# MCXN947_cm33_core0 register map
Vendor: nxp.com; File version: 1.0
CPU: CM33 r2p0, little endian, MPU, FPU, VTOR, 3 interrupt priority bits
Registers are 32-bit, read-write, reset 0x0 unless marked. A register's access mark holds for its fields unless they carry their own. Offsets are from the block's base; [hi:lo] are bit positions; lines under a group give offsets from that group; {n}, {i} and the like mark numbered series; 'fields as' and 'values as' point back to an identical list.

## AHBSC
Base 0x40120000
Same registers: AHBSC_ALIAS1 0x40121000, AHBSC_ALIAS2 0x40122000, AHBSC_ALIAS3 0x40123000
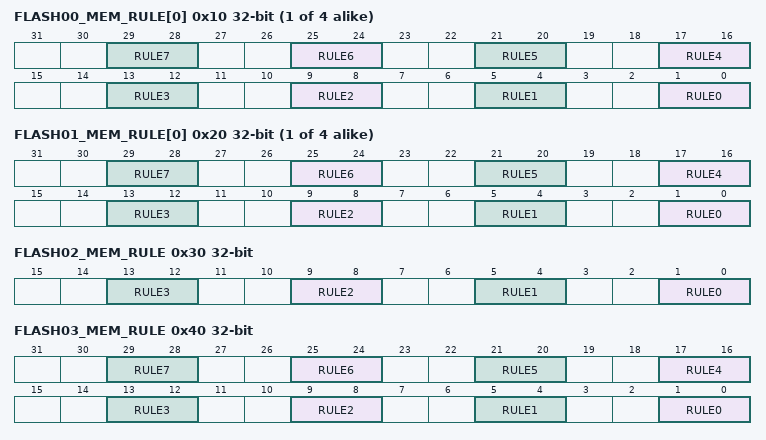
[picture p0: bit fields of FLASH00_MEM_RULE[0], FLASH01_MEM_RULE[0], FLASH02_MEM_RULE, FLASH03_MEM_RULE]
{0x10+4i} FLASH00_MEM_RULE[{i}] (i=0..3) — Flash Memory Rule
  [all] fields
    0=NONSECURE_NONPRIV_USER_ALLOWED (Non-secure and non-privilege user access allowed); 1=NONSECURE_PRIV_USER_ALLOWED (Non-secure and privilege access allowed); 2=SECURE_NONPRIV_USER_ALLOWED (Secure and non-privilege user access allowed); 3=SECURE_PRIV_USER_ALLOWED (Secure and privilege user access allowed)
  [4n+1:4n] RULE{n} (n=0..7)
{0x20+4i} FLASH01_MEM_RULE[{i}] (i=0..3) — Flash Memory Rule
  fields as FLASH00_MEM_RULE[0]
0x30 FLASH02_MEM_RULE — Flash Memory Rule
  [all] fields
    values as the fields of FLASH00_MEM_RULE[0]
  [4n+1:4n] RULE{n} (n=0..3)
0x40 FLASH03_MEM_RULE — Flash Memory Rule
  fields as FLASH00_MEM_RULE[0]
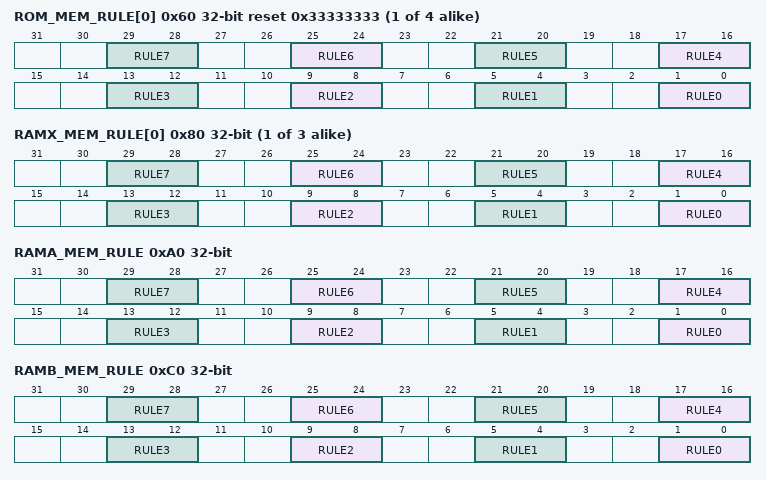
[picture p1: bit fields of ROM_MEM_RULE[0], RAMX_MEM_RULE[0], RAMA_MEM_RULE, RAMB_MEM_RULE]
{0x60+4i} ROM_MEM_RULE[{i}] (i=0..3) reset 0x33333333 — ROM Memory Rule
  fields as FLASH00_MEM_RULE[0]
{0x80+4i} RAMX_MEM_RULE[{i}] (i=0..2) — RAMX Memory Rule
  fields as FLASH00_MEM_RULE[0]
0xA0 RAMA_MEM_RULE — RAMA Memory Rule 0
  fields as FLASH00_MEM_RULE[0]
0xC0 RAMB_MEM_RULE — RAMB Memory Rule
  fields as FLASH00_MEM_RULE[0]
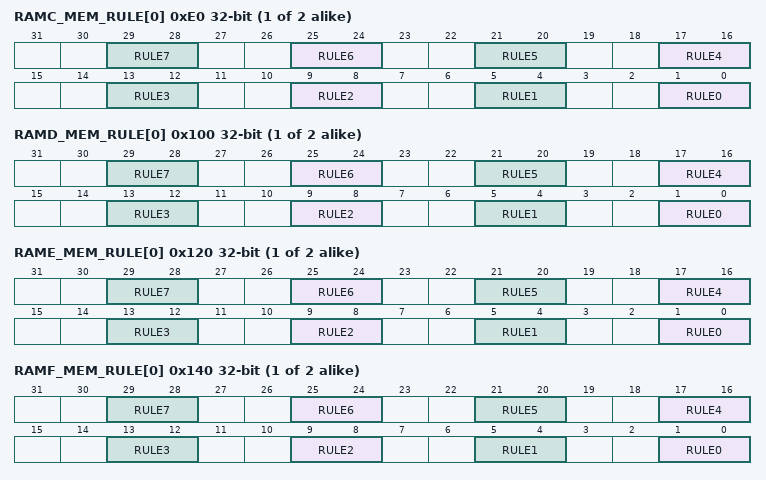
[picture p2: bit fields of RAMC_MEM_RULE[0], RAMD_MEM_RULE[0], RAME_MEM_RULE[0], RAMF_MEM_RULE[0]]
{0xE0+4i} RAMC_MEM_RULE[{i}] (i=0..1) — RAMC Memory Rule
  fields as FLASH00_MEM_RULE[0]
{0x100+4i} RAMD_MEM_RULE[{i}] (i=0..1) — RAMD Memory Rule
  fields as FLASH00_MEM_RULE[0]
{0x120+4i} RAME_MEM_RULE[{i}] (i=0..1) — RAME Memory Rule
  fields as FLASH00_MEM_RULE[0]
{0x140+4i} RAMF_MEM_RULE[{i}] (i=0..1) — RAMF Memory Rule
  fields as FLASH00_MEM_RULE[0]
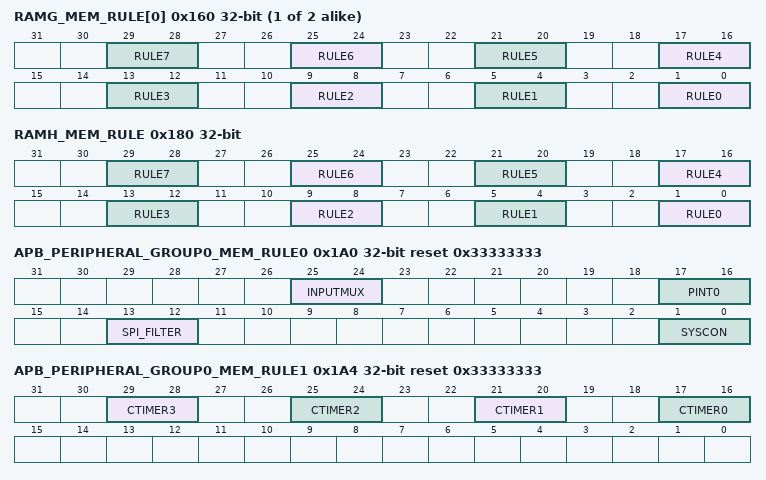
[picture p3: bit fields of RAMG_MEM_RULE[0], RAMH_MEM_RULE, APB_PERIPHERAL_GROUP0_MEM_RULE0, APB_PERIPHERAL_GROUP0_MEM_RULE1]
{0x160+4i} RAMG_MEM_RULE[{i}] (i=0..1) — RAMG Memory Rule
  fields as FLASH00_MEM_RULE[0]
0x180 RAMH_MEM_RULE — RAMH Memory Rule
  fields as FLASH00_MEM_RULE[0]
0x1A0 APB_PERIPHERAL_GROUP0_MEM_RULE0 reset 0x33333333 — APB Bridge Group 0 Memory Rule 0
  [all] fields
    values as the fields of FLASH00_MEM_RULE[0]
  [25:24] INPUTMUX
  [17:16] PINT0
  [13:12] SPI_FILTER — GPIO0
  [1:0] SYSCON
0x1A4 APB_PERIPHERAL_GROUP0_MEM_RULE1 reset 0x33333333 — APB Bridge Group 0 Memory Rule 1
  [all] fields
    values as the fields of FLASH00_MEM_RULE[0]
  [29:28] CTIMER3
  [25:24] CTIMER2
  [21:20] CTIMER1 write-1-clears
  [17:16] CTIMER0 write-1-clears
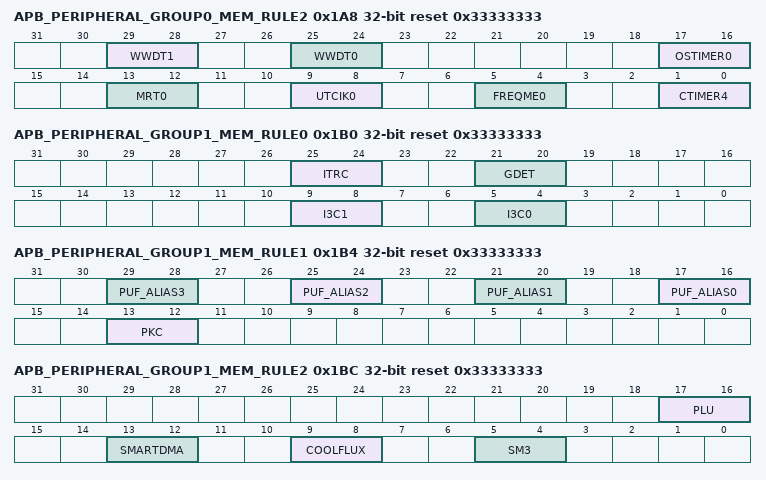
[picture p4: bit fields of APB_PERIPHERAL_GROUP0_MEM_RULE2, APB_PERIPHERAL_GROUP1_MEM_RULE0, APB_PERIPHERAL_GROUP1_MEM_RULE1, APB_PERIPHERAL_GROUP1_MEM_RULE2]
0x1A8 APB_PERIPHERAL_GROUP0_MEM_RULE2 reset 0x33333333 — APB Bridge Group 0 Rule 2
  [all] fields
    values as the fields of FLASH00_MEM_RULE[0]
  [29:28] WWDT1
  [25:24] WWDT0
  [17:16] OSTIMER0
  [13:12] MRT0
  [9:8] UTCIK0
  [5:4] FREQME0
  [1:0] CTIMER4
0x1AC APB_PERIPHERAL_GROUP0_MEM_RULE3 reset 0x33333333 — APB Bridge Group 0 Memory Rule 3
  [13:12] CACHE64_POLSEL0
    values as the fields of FLASH00_MEM_RULE[0]
0x1B0 APB_PERIPHERAL_GROUP1_MEM_RULE0 reset 0x33333333 — APB Bridge Group 1 Memory Rule 0
  [all] fields
    values as the fields of FLASH00_MEM_RULE[0]
  [25:24] ITRC
  [21:20] GDET
  [9:8] I3C1
  [5:4] I3C0
0x1B4 APB_PERIPHERAL_GROUP1_MEM_RULE1 reset 0x33333333 — APB Bridge Group 1 Memory Rule 1
  [all] fields
    values as the fields of FLASH00_MEM_RULE[0]
  [4n+17:4n+16] PUF_ALIAS{n} (n=0..3)
  [13:12] PKC
0x1BC APB_PERIPHERAL_GROUP1_MEM_RULE2 reset 0x33333333 — APB Bridge Group 1 Memory Rule 2
  [all] fields
    values as the fields of FLASH00_MEM_RULE[0]
  [17:16] PLU
  [13:12] SMARTDMA
  [9:8] COOLFLUX
  [5:4] SM3
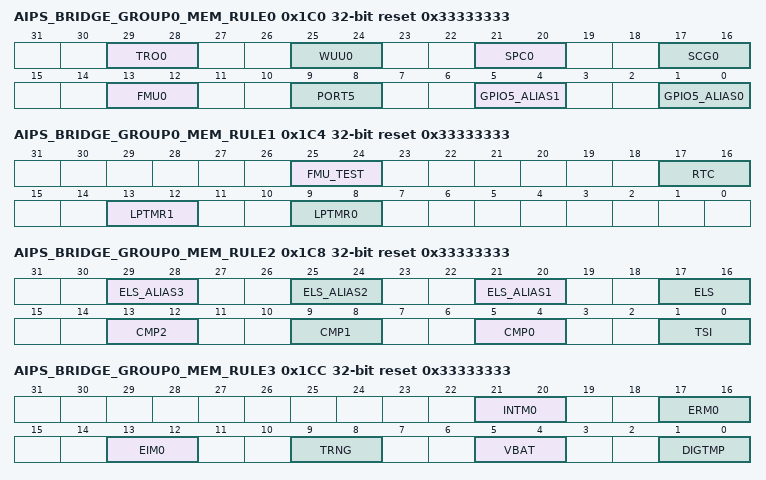
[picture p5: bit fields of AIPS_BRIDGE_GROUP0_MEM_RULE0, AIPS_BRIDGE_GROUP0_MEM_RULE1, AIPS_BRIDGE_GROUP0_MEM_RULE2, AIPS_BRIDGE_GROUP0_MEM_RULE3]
0x1C0 AIPS_BRIDGE_GROUP0_MEM_RULE0 reset 0x33333333 — AIPS Bridge Group 0 Memory Rule 0
  [all] fields
    values as the fields of FLASH00_MEM_RULE[0]
  [29:28] TRO0
  [25:24] WUU0
  [21:20] SPC0
  [17:16] SCG0
  [13:12] FMU0
  [9:8] PORT5
  [5:4] GPIO5_ALIAS1 — GPIO5_ALIAS2
  [1:0] GPIO5_ALIAS0
0x1C4 AIPS_BRIDGE_GROUP0_MEM_RULE1 reset 0x33333333 — AIPS Bridge Group 0 Memory Rule 1
  [all] fields
    values as the fields of FLASH00_MEM_RULE[0]
  [25:24] FMU_TEST
  [17:16] RTC
  [13:12] LPTMR1
  [9:8] LPTMR0
0x1C8 AIPS_BRIDGE_GROUP0_MEM_RULE2 reset 0x33333333 — AIPS Bridge Group 0 Memory Rule 2
  [all] fields
    values as the fields of FLASH00_MEM_RULE[0]
  [29:28] ELS_ALIAS3
  [25:24] ELS_ALIAS2
  [21:20] ELS_ALIAS1
  [17:16] ELS
  [13:12] CMP2
  [9:8] CMP1
  [5:4] CMP0
  [1:0] TSI
0x1CC AIPS_BRIDGE_GROUP0_MEM_RULE3 reset 0x33333333 — AIPS Bridge Group 0 Memory Rule 3
  [all] fields
    values as the fields of FLASH00_MEM_RULE[0]
  [21:20] INTM0
  [17:16] ERM0
  [13:12] EIM0
  [9:8] TRNG
  [5:4] VBAT
  [1:0] DIGTMP
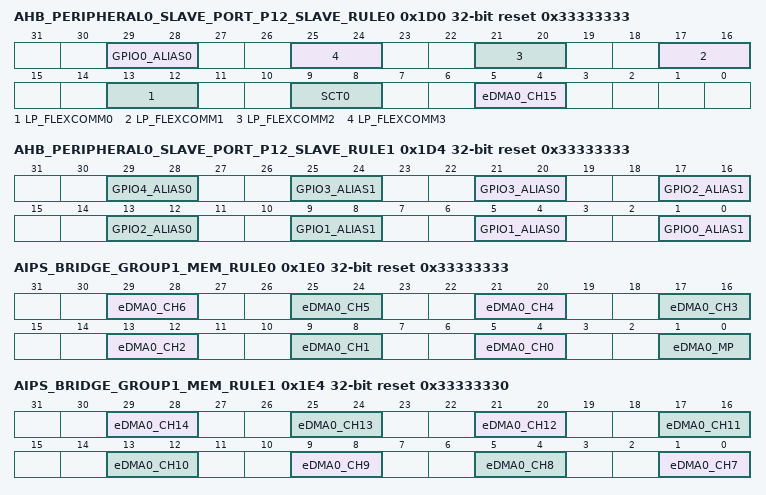
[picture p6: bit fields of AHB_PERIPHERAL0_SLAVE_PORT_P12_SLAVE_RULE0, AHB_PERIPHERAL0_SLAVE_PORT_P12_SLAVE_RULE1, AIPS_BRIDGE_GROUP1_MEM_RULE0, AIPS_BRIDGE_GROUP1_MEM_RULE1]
0x1D0 AHB_PERIPHERAL0_SLAVE_PORT_P12_SLAVE_RULE0 reset 0x33333333 — AHB Peripheral 0 Slave Port 12 Slave Rule 0
  [all] fields
    values as the fields of FLASH00_MEM_RULE[0]
  [29:28] GPIO0_ALIAS0
  [4n+13:4n+12] LP_FLEXCOMM{n} (n=0..3)
  [9:8] SCT0
  [5:4] eDMA0_CH15
0x1D4 AHB_PERIPHERAL0_SLAVE_PORT_P12_SLAVE_RULE1 reset 0x33333333 — AHB Peripheral 0 Slave Port 12 Slave Rule 1
  [all] fields
    values as the fields of FLASH00_MEM_RULE[0]
  [8n-3:8n-4] GPIO{n}_ALIAS0 (n=1..4)
  [8n+1:8n] GPIO{n}_ALIAS1 (n=0..3)
0x1D8 AHB_PERIPHERAL0_SLAVE_PORT_P12_SLAVE_RULE2 reset 0x33333333 — AHB Peripheral 0 Slave Port 12 Slave Rule 2
  [1:0] GPIO4_ALIAS1
    values as the fields of FLASH00_MEM_RULE[0]
0x1E0 AIPS_BRIDGE_GROUP1_MEM_RULE0 reset 0x33333333 — AIPS Bridge Group 1 Rule 0
  [all] fields
    values as the fields of FLASH00_MEM_RULE[0]
  [29:28] eDMA0_CH6
  [25:24] eDMA0_CH5
  [21:20] eDMA0_CH4
  [17:16] eDMA0_CH3 — FLEXSPI0 Registers
  [13:12] eDMA0_CH2
  [9:8] eDMA0_CH1
  [5:4] eDMA0_CH0
  [1:0] eDMA0_MP
0x1E4 AIPS_BRIDGE_GROUP1_MEM_RULE1 reset 0x33333330 — AIPS Bridge Group 1 Rule 1
  [all] fields
    values as the fields of FLASH00_MEM_RULE[0]
  [29:28] eDMA0_CH14
  [25:24] eDMA0_CH13
  [21:20] eDMA0_CH12
  [17:16] eDMA0_CH11 — FLEXSPI0
  [4n-27:4n-28] eDMA0_CH{n} (n=7..10)
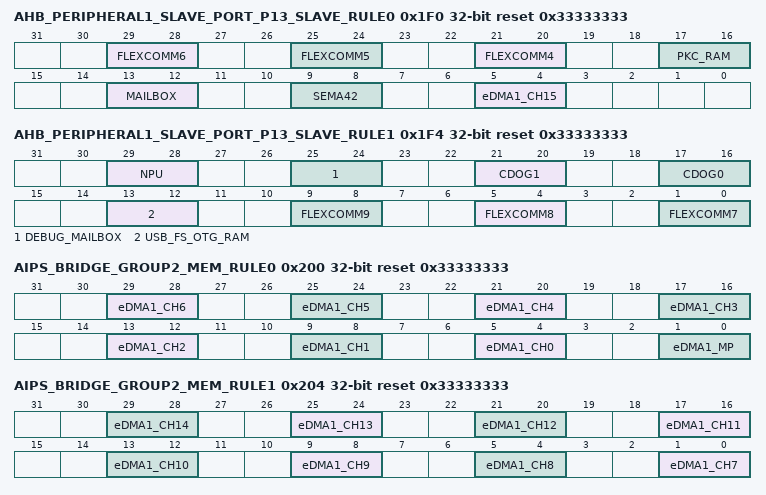
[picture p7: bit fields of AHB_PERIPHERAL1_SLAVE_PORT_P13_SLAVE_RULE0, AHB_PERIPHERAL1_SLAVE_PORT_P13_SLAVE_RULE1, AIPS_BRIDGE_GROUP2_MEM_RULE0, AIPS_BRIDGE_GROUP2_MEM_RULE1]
0x1F0 AHB_PERIPHERAL1_SLAVE_PORT_P13_SLAVE_RULE0 reset 0x33333333 — AHB Peripheral 1 Slave Port 13 Slave Rule 0
  [all] fields
    values as the fields of FLASH00_MEM_RULE[0]
  [29:28] FLEXCOMM6
  [25:24] FLEXCOMM5
  [21:20] FLEXCOMM4
  [17:16] PKC_RAM
  [13:12] MAILBOX
  [9:8] SEMA42
  [5:4] eDMA1_CH15
0x1F4 AHB_PERIPHERAL1_SLAVE_PORT_P13_SLAVE_RULE1 reset 0x33333333 — AHB Peripheral 1 Slave Port 13 Slave Rule 1
  [all] fields
    values as the fields of FLASH00_MEM_RULE[0]
  [29:28] NPU
  [25:24] DEBUG_MAILBOX
  [21:20] CDOG1
  [17:16] CDOG0
  [13:12] USB_FS_OTG_RAM
  [9:8] FLEXCOMM9
  [5:4] FLEXCOMM8
  [1:0] FLEXCOMM7
0x1F8 AHB_PERIPHERAL1_SLAVE_PORT_P13_SLAVE_RULE2 reset 0x33333333 — AHB Peripheral 1 Slave Port 13 Slave Rule 2
  [1:0] POWERQUAD
    values as the fields of FLASH00_MEM_RULE[0]
0x200 AIPS_BRIDGE_GROUP2_MEM_RULE0 reset 0x33333333 — AIPS Bridge Group 2 Rule 0
  [all] fields
    values as the fields of FLASH00_MEM_RULE[0]
  [4n+5:4n+4] eDMA1_CH{n} (n=0..6)
  [1:0] eDMA1_MP
0x204 AIPS_BRIDGE_GROUP2_MEM_RULE1 reset 0x33333333 — AIPS Bridge Group 2 Memory Rule 1
  [all] fields
    values as the fields of FLASH00_MEM_RULE[0]
  [4n-27:4n-28] eDMA1_CH{n} (n=7..14)
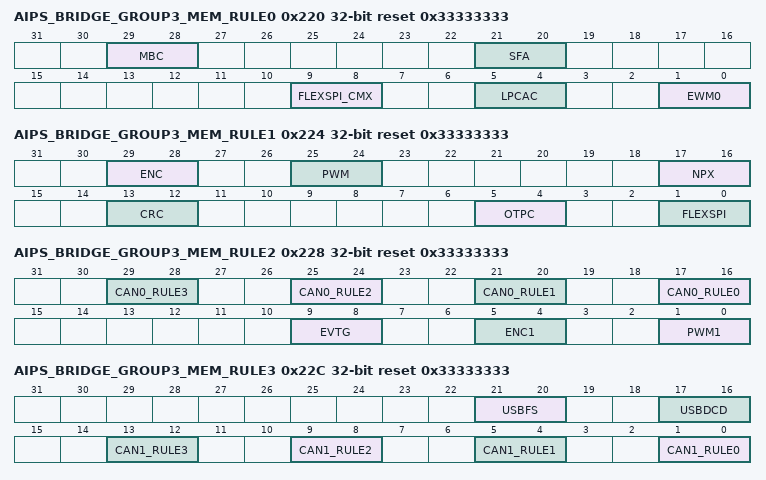
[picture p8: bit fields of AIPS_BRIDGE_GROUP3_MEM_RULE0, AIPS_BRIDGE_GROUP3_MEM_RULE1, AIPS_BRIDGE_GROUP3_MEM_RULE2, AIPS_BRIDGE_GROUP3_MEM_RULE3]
0x220 AIPS_BRIDGE_GROUP3_MEM_RULE0 reset 0x33333333 — AIPS Bridge Group 3 Rule 0
  [all] fields
    values as the fields of FLASH00_MEM_RULE[0]
  [29:28] MBC
  [21:20] SFA
  [9:8] FLEXSPI_CMX
  [5:4] LPCAC
  [1:0] EWM0
0x224 AIPS_BRIDGE_GROUP3_MEM_RULE1 reset 0x33333333 — AIPS Bridge Group 3 Memory Rule 1
  [all] fields
    values as the fields of FLASH00_MEM_RULE[0]
  [29:28] ENC
  [25:24] PWM
  [17:16] NPX
  [13:12] CRC
  [5:4] OTPC
  [1:0] FLEXSPI
0x228 AIPS_BRIDGE_GROUP3_MEM_RULE2 reset 0x33333333 — AIPS Bridge Group 3 Rule 2
  [all] fields
    values as the fields of FLASH00_MEM_RULE[0]
  [4n+17:4n+16] CAN0_RULE{n} (n=0..3)
  [9:8] EVTG
  [5:4] ENC1
  [1:0] PWM1
0x22C AIPS_BRIDGE_GROUP3_MEM_RULE3 reset 0x33333333 — AIPS Bridge Group 3 Rule 3
  [all] fields
    values as the fields of FLASH00_MEM_RULE[0]
  [21:20] USBFS
  [17:16] USBDCD
  [4n+1:4n] CAN1_RULE{n} (n=0..3)
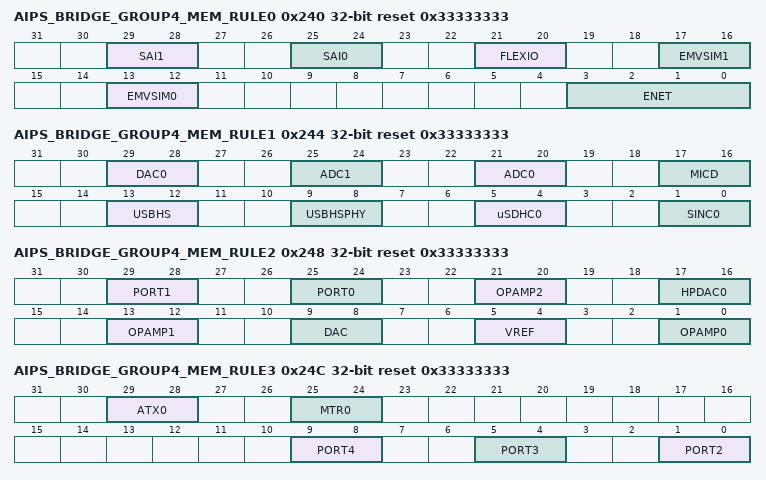
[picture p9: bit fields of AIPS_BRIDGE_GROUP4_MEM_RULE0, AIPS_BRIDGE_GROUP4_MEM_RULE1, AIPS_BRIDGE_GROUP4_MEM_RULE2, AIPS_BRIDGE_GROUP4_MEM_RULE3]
0x240 AIPS_BRIDGE_GROUP4_MEM_RULE0 reset 0x33333333 — AIPS Bridge Group 4 Rule 0
  [all] fields
    values as the fields of FLASH00_MEM_RULE[0]
  [29:28] SAI1
  [25:24] SAI0
  [21:20] FLEXIO
  [17:16] EMVSIM1
  [13:12] EMVSIM0
  [3:0] ENET
0x244 AIPS_BRIDGE_GROUP4_MEM_RULE1 reset 0x33333333 — AIPS Bridge Group 4 Rule 1
  [all] fields
    values as the fields of FLASH00_MEM_RULE[0]
  [29:28] DAC0
  [25:24] ADC1
  [21:20] ADC0
  [17:16] MICD
  [13:12] USBHS
  [9:8] USBHSPHY
  [5:4] uSDHC0
  [1:0] SINC0
0x248 AIPS_BRIDGE_GROUP4_MEM_RULE2 reset 0x33333333 — AIPS Bridge Group 4 Rule 2
  [all] fields
    values as the fields of FLASH00_MEM_RULE[0]
  [29:28] PORT1
  [25:24] PORT0
  [21:20] OPAMP2
  [17:16] HPDAC0
  [13:12] OPAMP1
  [9:8] DAC
  [5:4] VREF
  [1:0] OPAMP0
0x24C AIPS_BRIDGE_GROUP4_MEM_RULE3 reset 0x33333333 — AIPS Bridge Group 4 Rule 3
  [all] fields
    values as the fields of FLASH00_MEM_RULE[0]
  [29:28] ATX0
  [25:24] MTR0
  [9:8] PORT4
  [5:4] PORT3
  [1:0] PORT2
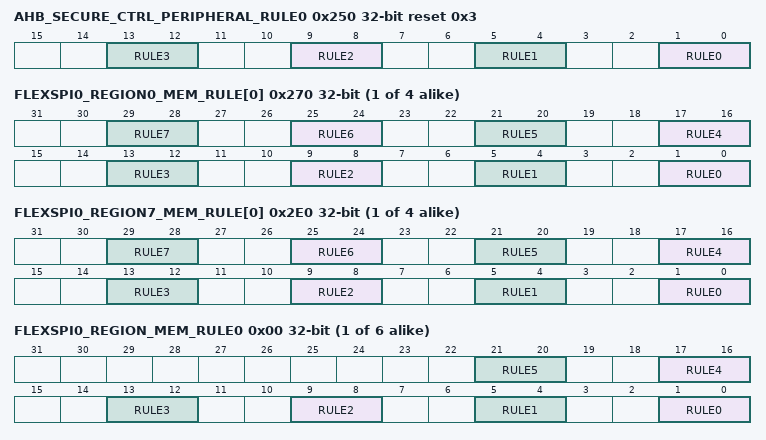
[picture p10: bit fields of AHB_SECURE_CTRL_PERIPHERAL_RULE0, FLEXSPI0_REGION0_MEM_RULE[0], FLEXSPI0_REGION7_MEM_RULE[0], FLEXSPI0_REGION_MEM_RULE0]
0x250 AHB_SECURE_CTRL_PERIPHERAL_RULE0 reset 0x3 — AHB Secure Control Peripheral Rule 0
  fields as FLASH02_MEM_RULE
{0x270+4i} FLEXSPI0_REGION0_MEM_RULE[{i}] (i=0..3) — FLEXSPI0 Region 0 Memory Rule
  fields as FLASH00_MEM_RULE[0]
{0x280+0x10*i} FLEXSPI0_REGION1_6_MEM_RULE[{i}] (i=0..5) group
  0x00 FLEXSPI0_REGION_MEM_RULE0 — FLEXSPI0 Region index Memory Rule 0
    [all] fields
      values as the fields of FLASH00_MEM_RULE[0]
    [4n+1:4n] RULE{n} (n=0..5)
{0x2E0+4i} FLEXSPI0_REGION7_MEM_RULE[{i}] (i=0..3) — FLEXSPI0 Region 7 Memory Rule
  fields as FLASH00_MEM_RULE[0]
{0x2F0+0x10*i} FLEXSPI0_REGION8_13_MEM_RULE[{i}] (i=0..5) group
  0x00 FLEXSPI0_REGION_MEM_RULE0 — FLEXSPI0 Region index Memory Rule 0
    fields as FLEXSPI0_REGION1_6_MEM_RULE[0].FLEXSPI0_REGION_MEM_RULE0
{0xE00+4i} SEC_VIO_ADDR[{i}] (i=0..31) ro — Security Violation Address
  [31:0] SEC_VIO_ADDR — Security violation address for AHB layer a reset value 0
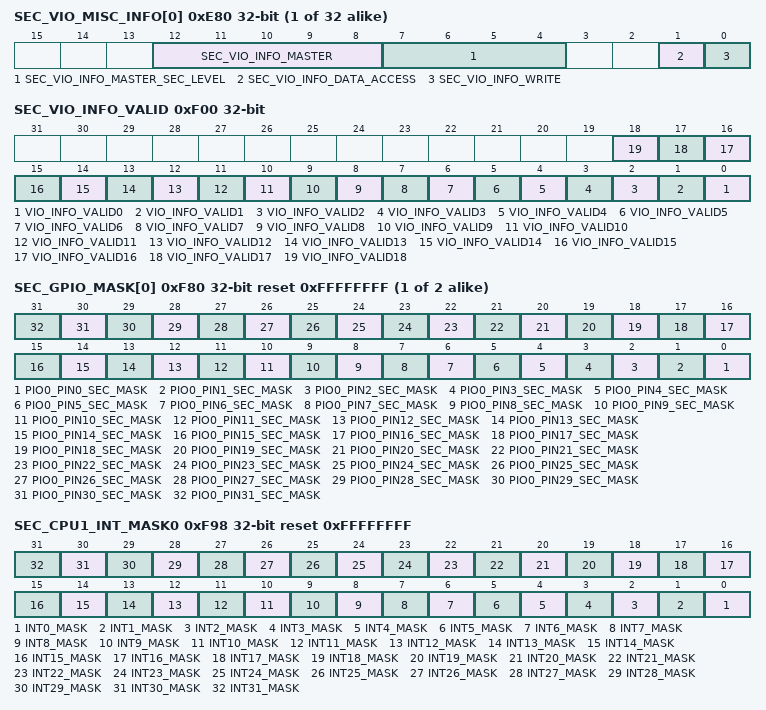
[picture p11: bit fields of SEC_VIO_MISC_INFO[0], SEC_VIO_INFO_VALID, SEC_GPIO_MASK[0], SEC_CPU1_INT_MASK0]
{0xE80+4i} SEC_VIO_MISC_INFO[{i}] (i=0..31) ro — Security Violation Miscellaneous Information at Address
  [12:8] SEC_VIO_INFO_MASTER — Security violation master number
    0=CPU0_CODE (M33 Code); 1=CPU0_SYS (M33 System); 2=CPU1_CODE (CPU1 (Mirco-CM33) Code); 3=SDMA_INSTR (SMARTDMA Instruction); 4=CPU1_SYS (CPU1 (Mirco-CM33) system); 5=SDMA_DATA (SMARTDMA Data); 6=eDMA0; 7=eDMA1; 8=PKC; 9=CSSV2 (ELS S50); 10=PQ (PKC M0); 11=NPUO (NPU Operands); 12=DSPI (DSP Instruction); 13=DSPX; 14=DSPY; 16=NPUD (NPU Data); 17=USB_FS; 18=ETHERNET; 19=USB_HS; 20=USDHC
  [7:4] SEC_VIO_INFO_MASTER_SEC_LEVEL — Security Violation Info Master Security Level
  [1] SEC_VIO_INFO_DATA_ACCESS — Security Violation Info Data Access
    0=CODE; 1=DATA
  [0] SEC_VIO_INFO_WRITE — Security violation access read/write indicator
    0=READ (Read access); 1=WRITE (Write access)
0xF00 SEC_VIO_INFO_VALID write-1-clears — Security Violation Info Validity for Address
  [all] fields
    0=NOT_VALID; 1=VALID
  [n] VIO_INFO_VALID{n} write-1-clears (n=0..18) — Violation information valid flag for AHB port {n}
{0xF80+4i} SEC_GPIO_MASK[{i}] (i=0..1) reset 0xFFFFFFFF — GPIO Mask for Port index
  [all] fields
    0=MASKED; 1=NOT_MASKED
  [n] PIO0_PIN{n}_SEC_MASK (n=0..31) — Mask bit
0xF98 SEC_CPU1_INT_MASK0 reset 0xFFFFFFFF — Secure Interrupt Mask 0 for CPU1
  [all] fields
    0=MASKED; 1=NOT_MASKED
  [n] INT{n}_MASK (n=0..31) — Mask bit
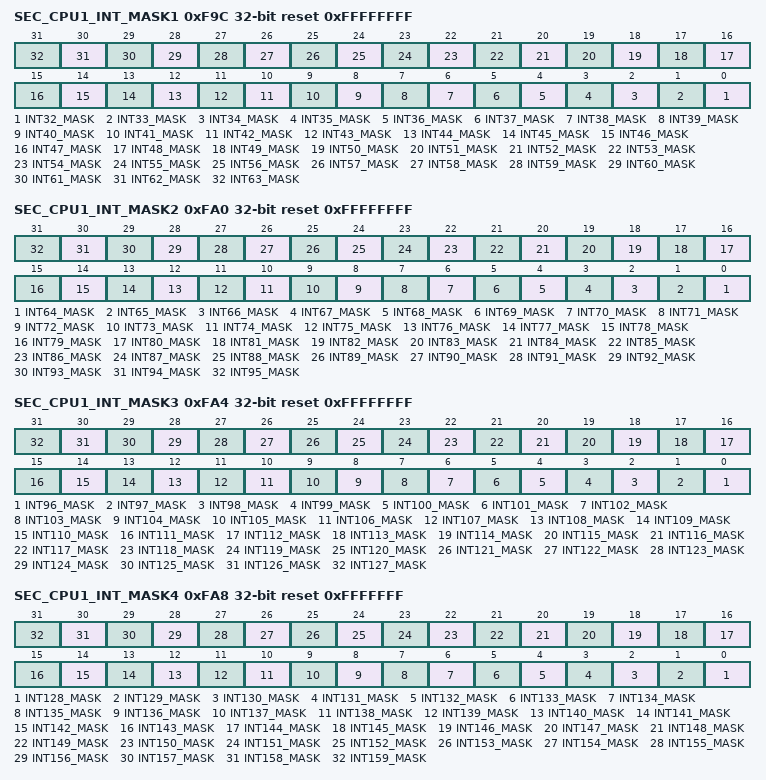
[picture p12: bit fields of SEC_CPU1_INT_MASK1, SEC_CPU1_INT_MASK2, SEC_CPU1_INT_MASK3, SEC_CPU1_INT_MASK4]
0xF9C SEC_CPU1_INT_MASK1 reset 0xFFFFFFFF — Secure Interrupt Mask 1 for CPU1
  [all] fields
    0=MASKED; 1=NOT_MASKED
  [n-32] INT{n}_MASK (n=32..63) — Mask bit
0xFA0 SEC_CPU1_INT_MASK2 reset 0xFFFFFFFF — Secure Interrupt Mask 2 for CPU1
  [all] fields
    0=MASKED; 1=NOT_MASKED
  [n-64] INT{n}_MASK (n=64..95) — Mask bit
0xFA4 SEC_CPU1_INT_MASK3 reset 0xFFFFFFFF — Secure Interrupt Mask 3 for CPU1
  [all] fields
    0=MASKED; 1=NOT_MASKED
  [n-96] INT{n}_MASK (n=96..127) — Mask bit
0xFA8 SEC_CPU1_INT_MASK4 reset 0xFFFFFFF — Secure Interrupt Mask 4 for CPU1
  [all] fields
    0=MASKED; 1=NOT_MASKED
  [n-128] INT{n}_MASK (n=128..159) — Mask bit
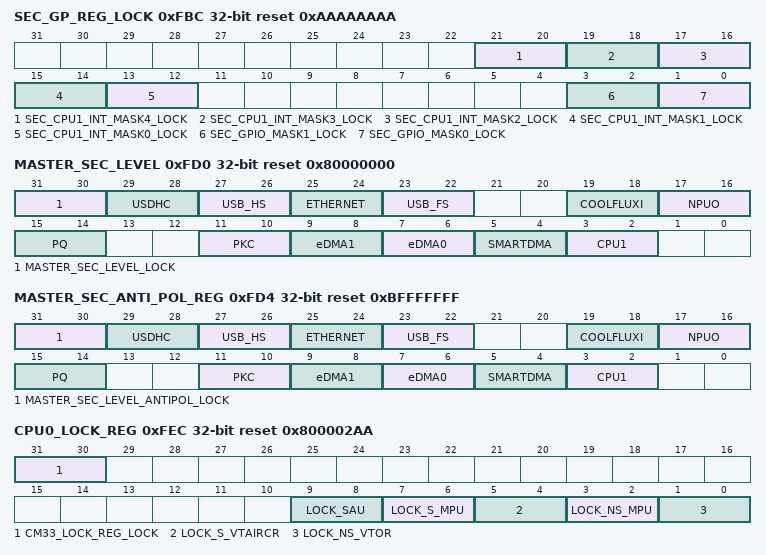
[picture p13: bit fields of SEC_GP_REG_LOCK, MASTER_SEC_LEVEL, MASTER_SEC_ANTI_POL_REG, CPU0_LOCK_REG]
0xFBC SEC_GP_REG_LOCK rw-once reset 0xAAAAAAAA — Secure Mask Lock
  [21:20] SEC_CPU1_INT_MASK4_LOCK
    1=CANNOT_BE_WRITTEN (SEC_CPU1_INT_MASK4 cannot be written); 2=CAN_BE_WRITTEN (SEC_CPU1_INT_MASK4 can be written)
  [19:18] SEC_CPU1_INT_MASK3_LOCK
    1=CANNOT_BE_WRITTEN (SEC_CPU1_INT_MASK3 cannot be written); 2=CAN_BE_WRITTEN (SEC_CPU1_INT_MASK3 can be written)
  [17:16] SEC_CPU1_INT_MASK2_LOCK
    1=CANNOT_BE_WRITTEN (SEC_CPU1_INT_MASK2 cannot be written); 2=CAN_BE_WRITTEN (SEC_CPU1_INT_MASK2 can be written)
  [15:14] SEC_CPU1_INT_MASK1_LOCK — SEC_GPIO_MASK1 Lock
    1=CANNOT_BE_WRITTEN (SEC_GPIO_MASK1 cannot be written); 2=CAN_BE_WRITTEN (SEC_GPIO_MASK1 can be written)
  [13:12] SEC_CPU1_INT_MASK0_LOCK — SSEC_CPU1_INT_MASK0 Lock
    1=CANNOT_BE_WRITTEN (SEC_GPIO_MASK0 cannot be written); 2=CAN_BE_WRITTEN (SEC_GPIO_MASK0 can be written)
  [3:2] SEC_GPIO_MASK1_LOCK — Secure GPIO _MASK1 Lock
    values as SEC_CPU1_INT_MASK1_LOCK
  [1:0] SEC_GPIO_MASK0_LOCK — Secure GPIO _MASK0 Lock
    values as SEC_CPU1_INT_MASK0_LOCK
0xFD0 MASTER_SEC_LEVEL reset 0x80000000 — Master Secure Level
  [31:30] MASTER_SEC_LEVEL_LOCK
    1=ENABLE (MASTER_SEC_LEVEL_LOCK cannot be written); 2=DISABLE (MASTER_SEC_LEVEL_LOCK can be written)
  [29:28] USDHC
    0=NONSECURE_NONPRIV_MASTER (Non-secure and non-privileged Master); 1=NONSECURE_PRIV_MASTER (Non-secure and privileged Master); 2=SECURE_NONPRIV_MASTER (Secure and non-privileged Master); 3=SECURE_PRIV_MASTER (Secure and privileged Master)
  [27:26] USB_HS
    values as USDHC
  [25:24] ETHERNET
    values as USDHC
  [23:22] USB_FS
    values as USDHC
  [19:18] COOLFLUXI — Coolflux Instruction
    values as USDHC
  [17:16] NPUO — NPU Operands
    values as USDHC
  [15:14] PQ — PowerQuad
    values as USDHC
  [11:10] PKC
    values as USDHC
  [9:8] eDMA1
    values as USDHC
  [7:6] eDMA0
    values as USDHC
  [5:4] SMARTDMA — SMARTDMA Data
    values as USDHC
  [3:2] CPU1
    values as USDHC
0xFD4 MASTER_SEC_ANTI_POL_REG reset 0xBFFFFFFF — Master Secure Level
  [31:30] MASTER_SEC_LEVEL_ANTIPOL_LOCK
    values as MASTER_SEC_LEVEL.MASTER_SEC_LEVEL_LOCK
  [29:28] USDHC
    0=NONSECURE_NONPRIV_MASTER (Secure and privileged Master); 1=NONSECURE_PRIV_MASTER (Secure and non-privileged Master); 2=SECURE_NONPRIV_MASTER (Non-secure and privileged Master); 3=SECURE_PRIV_MASTER (Non-secure and non-privileged Master)
  [27:26] USB_HS
    values as USDHC
  [25:24] ETHERNET
    values as USDHC
  [23:22] USB_FS
    values as USDHC
  [19:18] COOLFLUXI — Coolflux Instruction
    values as USDHC
  [17:16] NPUO — NPU Operands
    values as USDHC
  [15:14] PQ — PowerQuad
    values as USDHC
  [11:10] PKC
    values as USDHC
  [9:8] eDMA1
    values as USDHC
  [7:6] eDMA0
    values as USDHC
  [5:4] SMARTDMA — SMARTDMA Data
    values as USDHC
  [3:2] CPU1
    values as USDHC
0xFEC CPU0_LOCK_REG reset 0x800002AA — Miscellaneous CPU0 Control Signals
  [31:30] CM33_LOCK_REG_LOCK
    1=CM33_LOCK_REG_LOCK_EQ_1 (CM33_LOCK_REG_LOCK is 1); 2=CM33_LOCK_REG_LOCK_EQ_0 (CM33_LOCK_REG_LOCK is 0)
  [9:8] LOCK_SAU
    1=LOCK_SAU_EQ_1 (CM33 (CPU0) LOCK_SAU is 1); 2=LOCK_SAU_EQ_0 (CM33 (CPU0) LOCK_SAU is 0)
  [7:6] LOCK_S_MPU
    1=LOCK_S_MPU_EQ_1 (CM33 (CPU0) LOCK_S_MPU is 1); 2=LOCK_S_MPU_EQ_0 (CM33 (CPU0) LOCK_S_MPU is 0)
  [5:4] LOCK_S_VTAIRCR
    1=LOCK_S_VTAIRCR_EQ_1 (CM33 (CPU0) LOCK_S_VTAIRCR is 1); 2=LOCK_S_VTAIRCR_EQ_0 (CM33 (CPU0) LOCK_S_VTAIRCR is 0)
  [3:2] LOCK_NS_MPU
    1=LOCK_NS_MPU_EQ_1 (CM33 (CPU0) LOCK_NS_MPU is 1); 2=LOCK_NS_MPU_EQ_0 (CM33 (CPU0) LOCK_NS_MPU is 0)
  [1:0] LOCK_NS_VTOR
    1=LOCK_NS_VTOR_EQ_1 (CM33 (CPU0) LOCKNSVTOR is 1); 2=LOCK_NS_VTOR_EQ_0 (CM33 (CPU0) LOCKNSVTOR is 0)
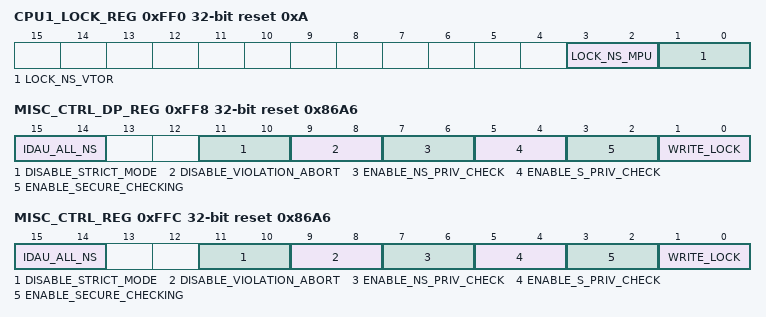
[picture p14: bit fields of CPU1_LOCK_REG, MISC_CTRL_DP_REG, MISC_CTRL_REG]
0xFF0 CPU1_LOCK_REG reset 0xA — Miscellaneous CPU1 Control Signals
  [3:2] LOCK_NS_MPU
    values as CPU0_LOCK_REG.LOCK_NS_MPU
  [1:0] LOCK_NS_VTOR
    values as CPU0_LOCK_REG.LOCK_NS_VTOR
0xFF8 MISC_CTRL_DP_REG reset 0x86A6 — Secure Control Duplicate
  [15:14] IDAU_ALL_NS — IDAU All Non-Secure
    1=DISABLED (IDAU is disabled, which means that all memories are attributed as non-secure memory.); 2=ENABLED (IDAU is enabled (restrictive mode))
  [11:10] DISABLE_STRICT_MODE
    1=AHBTM (Master strict mode is on and can access memories and peripherals at the same level or below that level.); 2=AHBSM1 (Master strict mode is disabled and can access memories and peripherals at same level only)
  [9:8] DISABLE_VIOLATION_ABORT
    1=NO_ABORT (The violation detected by the secure checker will not cause an abort, but a secure_violation_irq (interrupt request) will still be asserted and serviced by ISR.); 2=ABORT (The violation detected by the secure checker will cause an abort.)
  [7:6] ENABLE_NS_PRIV_CHECK — Enable Non-Secure Privilege Checking
    1=ENABLED (Enables the privilege checking of non-secure mode access.); 2=DISABLED (Disables the privilege checking of non-secure mode access.)
  [5:4] ENABLE_S_PRIV_CHECK — Enable Secure Privilege Checking
    1=ENABLED (Enables the privilege checking of secure mode access.); 2=DISABLED (Disables the privilege checking of secure mode access.)
  [3:2] ENABLE_SECURE_CHECKING
    1=ENABLED (Enables secure checking. Violation can be detected when the security level of a transaction does not meet the security rule of the slave or memory to be accessed.); 2=DISABLED (Disables secure checking. Even if the security level of a transaction does not conform to the security rule of the slave or memory, it will not be detected as a violation.)
  [1:0] WRITE_LOCK
    1=LOCKED (Writes to this register and to the Memory and Peripheral RULE registers are not allowed); 2=NOT_LOCKED (Writes to this register and to the Memory and Peripheral RULE registers are allowed)
0xFFC MISC_CTRL_REG reset 0x86A6 — Secure Control
  [15:14] IDAU_ALL_NS — IDAU All Non-Secure
    values as MISC_CTRL_DP_REG.IDAU_ALL_NS
  [11:10] DISABLE_STRICT_MODE
    1=AHBTM (Master strict mode is on and can access memories and peripherals at the same level or below that level); 2=AHBSM1 (Master strict mode is disabled and can access memories and peripherals at same level only)
  [9:8] DISABLE_VIOLATION_ABORT
    values as MISC_CTRL_DP_REG.DISABLE_VIOLATION_ABORT
  [7:6] ENABLE_NS_PRIV_CHECK — Enable Non-Secure Privilege Checking
    1=ENABLED (Enables privilege checking of non-secure mode access.); 2=DISABLED (Disables privilege checking of non-secure mode access is disabled.)
  [5:4] ENABLE_S_PRIV_CHECK — Enable Secure Privilege Checking
    1=ENABLED (Enables privilege checking of secure mode access.); 2=DISABLED (Disables privilege checking of secure mode access.)
  [3:2] ENABLE_SECURE_CHECKING
    values as MISC_CTRL_DP_REG.ENABLE_SECURE_CHECKING
  [1:0] WRITE_LOCK
    values as MISC_CTRL_DP_REG.WRITE_LOCK
